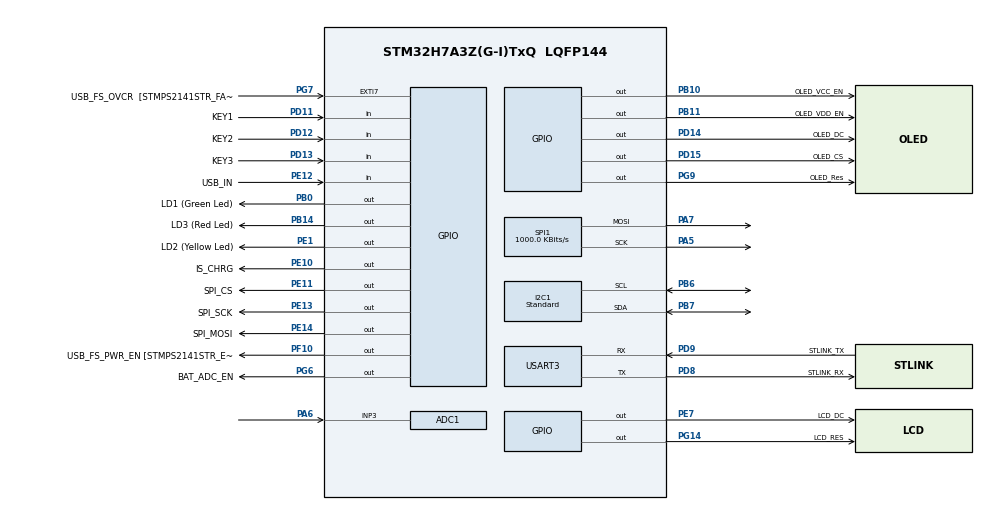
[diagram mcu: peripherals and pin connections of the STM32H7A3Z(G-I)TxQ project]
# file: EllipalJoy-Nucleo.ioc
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ADC1.Channel-0\#ChannelRegularConversion=ADC_CHANNEL_3
ADC1.NbrOfConversionFlag=1
ADC1.OffsetNumber-0\#ChannelRegularConversion=ADC_OFFSET_NONE
ADC1.OffsetSignedSaturation-0\#ChannelRegularConversion=DISABLE
ADC1.Rank-0\#ChannelRegularConversion=1
ADC1.SamplingTime-0\#ChannelRegularConversion=ADC_SAMPLETIME_1CYCLE_5
ADC1.master=1
I2C1.CustomTiming=Enabled
I2C1.I2C_Speed_Mode=I2C_Standard
I2C1.OwnAddress=0x3C
Mcu.Family=STM32H7
Mcu.Name=STM32H7A3Z(G-I)TxQ
Mcu.Package=LQFP144
NVIC.PriorityGroup=NVIC_PRIORITYGROUP_4
PA10.GPIO_Label=USB_FS_ID [ZX62RD-AB-5P8_ID]
PA10.Signal=USB_OTG_HS_ID
PA11.GPIO_Label=USB_FS_N [USBLC6-2SC6_IO_1]
PA11.Signal=USB_OTG_HS_DM
PA12.GPIO_Label=USB_FS_P [USBLC6-2SC6_IO_2]
PA12.Signal=USB_OTG_HS_DP
PA13.Mode=Serial_Wire
PA13.Signal=DEBUG_JTMS-SWDIO
PA14.Mode=Serial_Wire
PA14.Signal=DEBUG_JTCK-SWCLK
PA5.Mode=TX_Only_Simplex_Unidirect_Master
PA5.Signal=SPI1_SCK
PA6.Signal=ADCx_INP3
PA7.Mode=TX_Only_Simplex_Unidirect_Master
PA7.Signal=SPI1_MOSI
PA9.GPIO_Label=USB_FS_VBUS  [ZX62RD-AB-5P8_VBUS]
PA9.Signal=USB_OTG_HS_VBUS
PB0.GPIO_Label=LD1 (Green Led)
PB0.Signal=GPIO_Output
PB10.GPIO_Label=OLED_VCC_EN
PB10.Signal=GPIO_Output
PB11.GPIO_Label=OLED_VDD_EN
PB11.PinState=GPIO_PIN_SET
PB11.Signal=GPIO_Output
PB14.GPIO_Label=LD3 (Red Led)
PB14.Signal=GPIO_Output
PB6.Mode=I2C
PB6.Signal=I2C1_SCL
PB7.Mode=I2C
PB7.Signal=I2C1_SDA
PC14-OSC32_IN.GPIO_Label=OSC32_IN
PC14-OSC32_IN.Signal=RCC_OSC32_IN
PC15-OSC32_OUT.GPIO_Label=OSC32_OUT
PC15-OSC32_OUT.Signal=RCC_OSC32_OUT
PD11.GPIO_Label=KEY1
PD11.GPIO_PuPd=GPIO_PULLUP
PD11.Signal=GPIO_Input
PD12.GPIO_Label=KEY2
PD12.GPIO_PuPd=GPIO_PULLUP
PD12.Signal=GPIO_Input
PD13.GPIO_Label=KEY3
PD13.GPIO_PuPd=GPIO_PULLUP
PD13.Signal=GPIO_Input
PD14.GPIO_Label=OLED_DC
PD14.Signal=GPIO_Output
PD15.GPIO_Label=OLED_CS
PD15.Signal=GPIO_Output
PD8.GPIO_Label=STLINK_RX
PD8.Mode=Asynchronous
PD8.Signal=USART3_TX
PD9.GPIO_Label=STLINK_TX
PD9.Mode=Asynchronous
PD9.Signal=USART3_RX
PE1.GPIO_Label=LD2 (Yellow Led)
PE1.Signal=GPIO_Output
PE10.GPIO_Label=IS_CHRG
PE10.GPIO_PuPd=GPIO_PULLUP
PE10.Signal=GPIO_Output
PE11.GPIO_Label=SPI_CS
PE11.Signal=GPIO_Output
PE12.GPIO_Label=USB_IN
PE12.GPIO_PuPd=GPIO_PULLDOWN
PE12.Signal=GPIO_Input
PE13.GPIO_Label=SPI_SCK
PE13.Signal=GPIO_Output
PE14.GPIO_Label=SPI_MOSI
PE14.Signal=GPIO_Output
PE7.GPIO_Label=LCD_DC
PE7.Signal=GPIO_Output
PF10.GPIO_Label=USB_FS_PWR_EN [STMPS2141STR_EN]
PF10.Signal=GPIO_Output
PG14.GPIO_Label=LCD_RES
PG14.Signal=GPIO_Output
PG6.GPIO_Label=BAT_ADC_EN
PG6.PinState=GPIO_PIN_SET
PG6.Signal=GPIO_Output
PG7.GPIO_Label=USB_FS_OVCR  [STMPS2141STR_FAULT]
PG7.Signal=GPXTI7
PG9.GPIO_Label=OLED_Res
PG9.Signal=GPIO_Output
PH0-OSC_IN.GPIO_Label=PH0-MCU
PH0-OSC_IN.Signal=RCC_OSC_IN
PH1-OSC_OUT.GPIO_Label=PH1-MCU
PH1-OSC_OUT.Signal=RCC_OSC_OUT
ProjectManager.HeapSize=0x200
ProjectManager.StackSize=0x400
ProjectManager.TargetToolchain=STM32CubeIDE
RCC.ADCFreq_Value=129000000
RCC.APB1Freq_Value=64000000
RCC.APB2Freq_Value=64000000
RCC.APB3Freq_Value=64000000
RCC.APB4Freq_Value=64000000
RCC.CortexFreq_Value=64000000
RCC.DIVM1=4
RCC.DIVM3=1
RCC.DIVN1=8
RCC.DIVN3=24
RCC.DIVQ1=4
RCC.HCLKFreq_Value=64000000
RCC.HSE_VALUE=8000000
RCC.PLLFRACN=0
RCC.PWR_Regulator_Voltage_Scale=PWR_REGULATOR_VOLTAGE_SCALE0
RCC.SYSCLKFreq_VALUE=64000000
RCC.SYSCLKSource=RCC_SYSCLKSOURCE_PLLCLK
RCC.SupplySource=PWR_DIRECT_SMPS_SUPPLY
RCC.USBCLockSelection=RCC_USBCLKSOURCE_HSI48
RCC.USBFreq_Value=48000000
SH.ADCx_INP3.0=ADC1_INP3,IN3-Single-Ended
SPI1.BaudRatePrescaler=SPI_BAUDRATEPRESCALER_32
SPI1.CalculateBaudRate=1000.0 KBits/s
SPI1.DataSize=SPI_DATASIZE_8BIT
SPI1.Direction=SPI_DIRECTION_2LINES_TXONLY
SPI1.Mode=SPI_MODE_MASTER
SPI1.NSSPMode=SPI_NSS_PULSE_ENABLE
SPI1.VirtualType=VM_MASTER
USART3.VirtualMode-Asynchronous=VM_ASYNC
VP_RNG_VS_RNG.Mode=RNG_Activate
board=NUCLEO-H7A3ZI-Q

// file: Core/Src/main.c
/* USER CODE BEGIN Header */
/**
  ******************************************************************************
  * @file           : main.c
  * @brief          : Main program body
  ******************************************************************************
  * @attention
  *
  * Copyright (c) 2022 STMicroelectronics.
  * All rights reserved.
  *
  * This software is licensed under terms that can be found in the LICENSE file
  * in the root directory of this software component.
  * If no LICENSE file comes with this software, it is provided AS-IS.
  *
  ******************************************************************************
  */
/* USER CODE END Header */
#include "main.h"
#include "adc.h"
#include "i2c.h"
#include "rng.h"
#include "spi.h"
#include "usart.h"
#include "gpio.h"

/* USER CODE BEGIN Includes */
#include "includes.h"
/* USER CODE END Includes */

void SystemClock_Config(void);

int main(void)
{

  /* MCU Configuration--------------------------------------------------------*/

  /* Reset of all peripherals, Initializes the Flash interface and the Systick. */
  HAL_Init();

  /* Configure the system clock */
  SystemClock_Config();

  /* Initialize all configured peripherals */
  MX_GPIO_Init();
  MX_RNG_Init();
  MX_USART3_UART_Init();
  MX_ADC1_Init();
  MX_I2C1_Init();
  MX_SPI1_Init();
  /* USER CODE BEGIN 2 */
	HAL_ADCEx_Calibration_Start(&hadc1, ADC_CALIB_OFFSET, ADC_SINGLE_ENDED);
	HAL_ADC_Start(&hadc1);
	__HAL_UART_ENABLE_IT(&huart3, UART_IT_RXNE);

	CommandInit();
	ServiceInit();

	DBG_LOG("System start.");

  /* USER CODE END 2 */

  /* Infinite loop */
  /* USER CODE BEGIN WHILE */
  while (1)
  {
	CommandReceivePolling();
	ButtonScanPolling();
	ServicePolling();
    /* USER CODE END WHILE */

  }
}

void SystemClock_Config(void)
{
  RCC_OscInitTypeDef RCC_OscInitStruct = {0};
  RCC_ClkInitTypeDef RCC_ClkInitStruct = {0};

  /** Supply configuration update enable
  */
  HAL_PWREx_ConfigSupply(PWR_DIRECT_SMPS_SUPPLY);

  /** Configure the main internal regulator output voltage
  */
  __HAL_PWR_VOLTAGESCALING_CONFIG(PWR_REGULATOR_VOLTAGE_SCALE0);

  while(!__HAL_PWR_GET_FLAG(PWR_FLAG_VOSRDY)) {}

  /** Macro to configure the PLL clock source
  */
  __HAL_RCC_PLL_PLLSOURCE_CONFIG(RCC_PLLSOURCE_HSI);

  /** Initializes the RCC Oscillators according to the specified parameters
  * in the RCC_OscInitTypeDef structure.
  */
  RCC_OscInitStruct.OscillatorType = RCC_OSCILLATORTYPE_HSI48|RCC_OSCILLATORTYPE_HSI;
  RCC_OscInitStruct.HSIState = RCC_HSI_DIV1;
  RCC_OscInitStruct.HSICalibrationValue = RCC_HSICALIBRATION_DEFAULT;
  RCC_OscInitStruct.HSI48State = RCC_HSI48_ON;
  RCC_OscInitStruct.PLL.PLLState = RCC_PLL_ON;
  RCC_OscInitStruct.PLL.PLLSource = RCC_PLLSOURCE_HSI;
  RCC_OscInitStruct.PLL.PLLM = 4;
  RCC_OscInitStruct.PLL.PLLN = 8;
  RCC_OscInitStruct.PLL.PLLP = 2;
  RCC_OscInitStruct.PLL.PLLQ = 4;
  RCC_OscInitStruct.PLL.PLLR = 2;
  RCC_OscInitStruct.PLL.PLLRGE = RCC_PLL1VCIRANGE_3;
  RCC_OscInitStruct.PLL.PLLVCOSEL = RCC_PLL1VCOWIDE;
  RCC_OscInitStruct.PLL.PLLFRACN = 0;
  if (HAL_RCC_OscConfig(&RCC_OscInitStruct) != HAL_OK)
  {
    Error_Handler();
  }

  /** Initializes the CPU, AHB and APB buses clocks
  */
  RCC_ClkInitStruct.ClockType = RCC_CLOCKTYPE_HCLK|RCC_CLOCKTYPE_SYSCLK
                              |RCC_CLOCKTYPE_PCLK1|RCC_CLOCKTYPE_PCLK2
                              |RCC_CLOCKTYPE_D3PCLK1|RCC_CLOCKTYPE_D1PCLK1;
  RCC_ClkInitStruct.SYSCLKSource = RCC_SYSCLKSOURCE_PLLCLK;
  RCC_ClkInitStruct.SYSCLKDivider = RCC_SYSCLK_DIV1;
  RCC_ClkInitStruct.AHBCLKDivider = RCC_HCLK_DIV1;
  RCC_ClkInitStruct.APB3CLKDivider = RCC_APB3_DIV1;
  RCC_ClkInitStruct.APB1CLKDivider = RCC_APB1_DIV1;
  RCC_ClkInitStruct.APB2CLKDivider = RCC_APB2_DIV1;
  RCC_ClkInitStruct.APB4CLKDivider = RCC_APB4_DIV1;

  if (HAL_RCC_ClockConfig(&RCC_ClkInitStruct, FLASH_LATENCY_1) != HAL_OK)
  {
    Error_Handler();
  }
}

void Error_Handler(void)
{
  __disable_irq();
  while (1)
  {
  }
}
